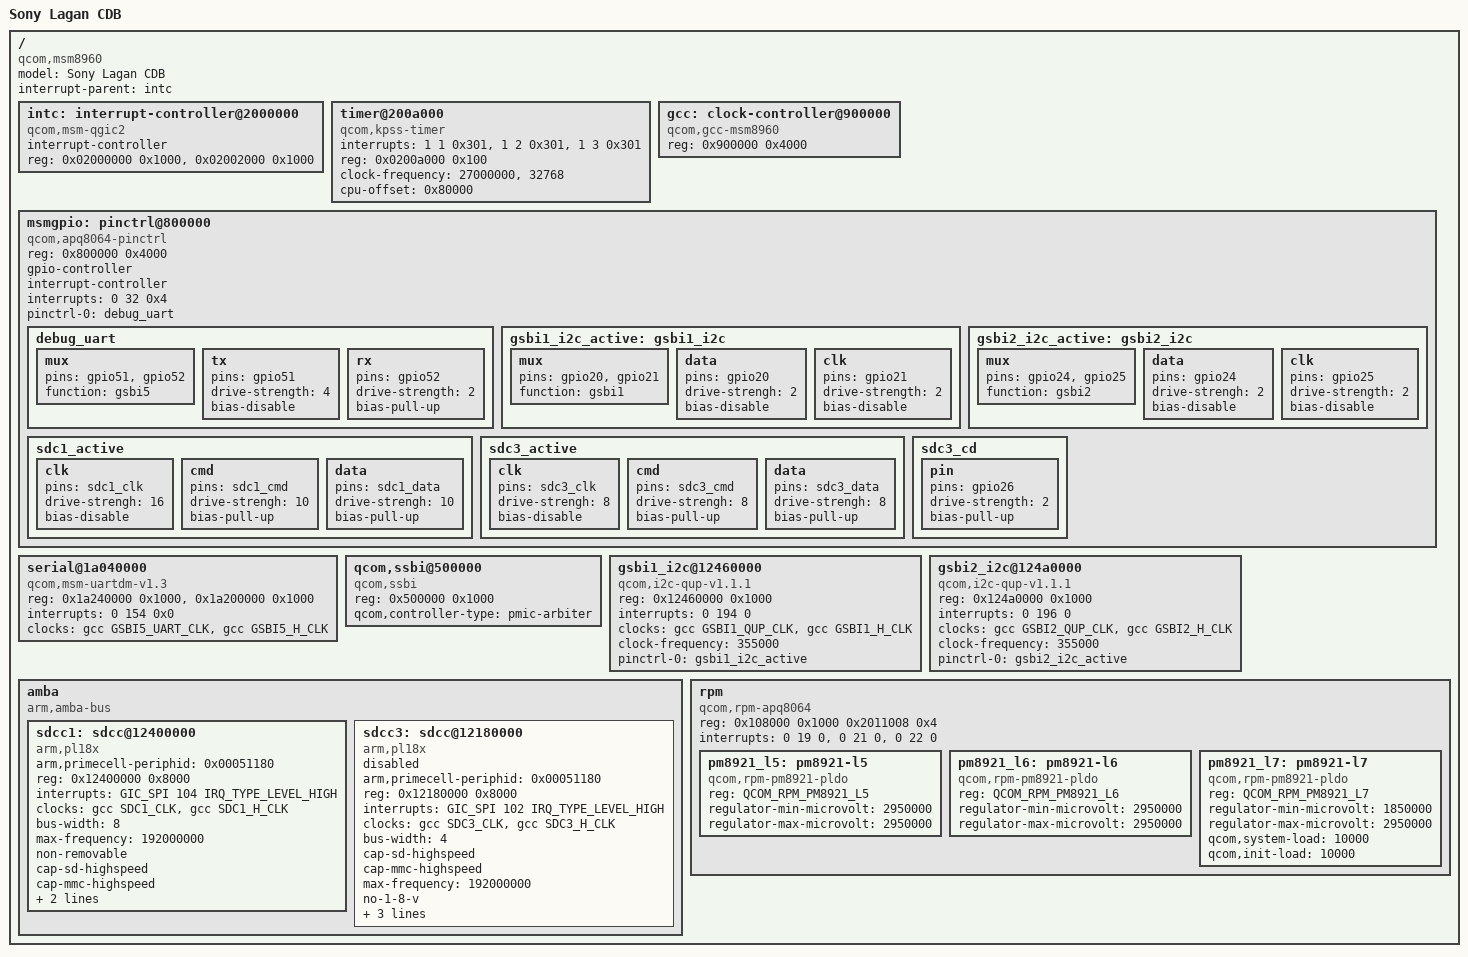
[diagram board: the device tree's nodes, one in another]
/dts-v1/;

#include "skeleton.dtsi"
#include <dt-bindings/interrupt-controller/arm-gic.h>
#include <dt-bindings/clock/qcom,gcc-msm8960.h>

#include <dt-bindings/mfd/qcom_rpm.h>

/ {
	model = "Sony Lagan CDB";
	compatible = "qcom,msm8960";
	interrupt-parent = <&intc>;

	intc: interrupt-controller@2000000 {
		compatible = "qcom,msm-qgic2";
		interrupt-controller;
		#interrupt-cells = <3>;
		reg = < 0x02000000 0x1000 >,
		      < 0x02002000 0x1000 >;
	};

	timer@200a000 {
		compatible = "qcom,kpss-timer", "qcom,msm-timer";
		interrupts = <1 1 0x301>,
			     <1 2 0x301>,
			     <1 3 0x301>;
		reg = <0x0200a000 0x100>;
		clock-frequency = <27000000>,
				  <32768>;
		cpu-offset = <0x80000>;
	};

	gcc: clock-controller@900000 {
		compatible = "qcom,gcc-msm8960";
		reg = <0x900000 0x4000>;
		#clock-cells = <1>;
		#reset-cells = <1>;
	};

	msmgpio: pinctrl@800000 {
		compatible = "qcom,apq8064-pinctrl";
		reg = <0x800000 0x4000>;

		gpio-controller;
		#gpio-cells = <2>;
		interrupt-controller;
		#interrupt-cells = <2>;
		interrupts = <0 32 0x4>;

		pinctrl-names = "default";
		pinctrl-0 = <&debug_uart>;

		debug_uart: debug_uart {
			mux {
				pins = "gpio51", "gpio52";
				function = "gsbi5";
			};

			tx {
				pins = "gpio51";
				drive-strength = <4>;
				bias-disable;
			};

			rx {
				pins = "gpio52";
				drive-strength = <2>;
				bias-pull-up;
			};
		};

		gsbi1_i2c_active: gsbi1_i2c {
			mux {
				pins = "gpio20", "gpio21";
				function = "gsbi1";
			};

			data {
				pins = "gpio20";
				drive-strengh = <2>;
				bias-disable;
			};

			clk {
				pins = "gpio21";
				drive-strength = <2>;
				bias-disable;
			};
		};

		gsbi2_i2c_active: gsbi2_i2c {
			mux {
				pins = "gpio24", "gpio25";
				function = "gsbi2";
			};

			data {
				pins = "gpio24";
				drive-strengh = <2>;
				bias-disable;
			};

			clk {
				pins = "gpio25";
				drive-strength = <2>;
				bias-disable;
			};
		};

		sdc1_active: sdc1_active {
			clk {
				pins = "sdc1_clk";
				drive-strengh = <16>;
				bias-disable;
			};

			cmd {
				pins = "sdc1_cmd";
				drive-strengh = <10>;
				bias-pull-up;
			};

			data {
				pins = "sdc1_data";
				drive-strengh = <10>;
				bias-pull-up;
			};
		};

		sdc3_active: sdc3_active {
			clk {
				pins = "sdc3_clk";
				drive-strengh = <8>;
				bias-disable;
			};

			cmd {
				pins = "sdc3_cmd";
				drive-strengh = <8>;
				bias-pull-up;
			};

			data {
				pins = "sdc3_data";
				drive-strengh = <8>;
				bias-pull-up;
			};
		 };

		sdc3_cd: sdc3_cd {
			pin {
				pins = "gpio26";
				drive-strength = <2>;
				bias-pull-up;
			};
		};
	};

	serial@1a040000 {
		compatible = "qcom,msm-uartdm-v1.3", "qcom,msm-uartdm";
		reg = <0x1a240000 0x1000>,
		      <0x1a200000 0x1000>;
		interrupts = <0 154 0x0>;
		clocks = <&gcc GSBI5_UART_CLK>, <&gcc GSBI5_H_CLK>;
		clock-names = "core", "iface";
	};

	qcom,ssbi@500000 {
		compatible = "qcom,ssbi";
		reg = <0x500000 0x1000>;
		qcom,controller-type = "pmic-arbiter";
	};

	gsbi1_i2c@12460000 {
		compatible = "qcom,i2c-qup-v1.1.1";
		reg = <0x12460000 0x1000>;
		interrupts = <0 194 0>;

		clocks = <&gcc GSBI1_QUP_CLK>, <&gcc GSBI1_H_CLK>;
		clock-names = "core", "iface";

		clock-frequency = <355000>;

		#address-cells = <1>;
		#size-cells = <0>;

		pinctrl-names = "default";
		pinctrl-0 = <&gsbi1_i2c_active>;
	};

	gsbi2_i2c@124a0000 {
		compatible = "qcom,i2c-qup-v1.1.1";
		reg = <0x124a0000 0x1000>;
		interrupts = <0 196 0>;

		clocks = <&gcc GSBI2_QUP_CLK>, <&gcc GSBI2_H_CLK>;
		clock-names = "core", "iface";

		clock-frequency = <355000>;

		#address-cells = <1>;
		#size-cells = <0>;

		pinctrl-names = "default";
		pinctrl-0 = <&gsbi2_i2c_active>;
	};

	amba {
		compatible = "arm,amba-bus";
		#address-cells = <1>;
		#size-cells = <1>;
		ranges;

		sdcc1: sdcc@12400000 {
			compatible      = "arm,pl18x", "arm,primecell";
			arm,primecell-periphid = <0x00051180>;
			reg             = <0x12400000 0x8000>;
			interrupts      = <GIC_SPI 104 IRQ_TYPE_LEVEL_HIGH>;
			interrupt-names = "cmd_irq";
			clocks          = <&gcc SDC1_CLK>, <&gcc SDC1_H_CLK>;
			clock-names     = "mclk", "apb_pclk";
			bus-width       = <8>;
			max-frequency   = <192000000>;
			non-removable;
			cap-sd-highspeed;
			cap-mmc-highspeed;
			vmmc-supply = <&pm8921_l5>;

			pinctrl-names = "default";
			pinctrl-0 = <&sdc1_active>;
		};

		sdcc3: sdcc@12180000 {
			compatible      = "arm,pl18x", "arm,primecell";
			arm,primecell-periphid = <0x00051180>;
			status = "NO!";
			reg             = <0x12180000 0x8000>;
			interrupts      = <GIC_SPI 102 IRQ_TYPE_LEVEL_HIGH>;
			interrupt-names = "cmd_irq";
			clocks          = <&gcc SDC3_CLK>, <&gcc SDC3_H_CLK>;
			clock-names     = "mclk", "apb_pclk";
			bus-width       = <4>;
			cap-sd-highspeed;
			cap-mmc-highspeed;
			max-frequency   = <192000000>;
			no-1-8-v;
			vmmc-supply = <&pm8921_l6>;
			vqmmc-supply = <&pm8921_l7>;

			pinctrl-names = "default";
			pinctrl-0 = <&sdc3_active &sdc3_cd>;
		};
	};

	rpm {
		compatible = "qcom,rpm-apq8064";
		reg = <0x108000 0x1000 0x2011008 0x4>;

		interrupts = <0 19 0>, <0 21 0>, <0 22 0>;
		interrupt-names = "ack", "err", "wakeup";

		#address-cells = <1>;
		#size-cells = <0>;

		pm8921_l5: pm8921-l5 {
			compatible = "qcom,rpm-pm8921-pldo";
			reg = <QCOM_RPM_PM8921_L5>;

			regulator-min-microvolt = <2950000>;
			regulator-max-microvolt = <2950000>;
		};

		pm8921_l6: pm8921-l6 {
			compatible = "qcom,rpm-pm8921-pldo";
			reg = <QCOM_RPM_PM8921_L6>;

			regulator-min-microvolt = <2950000>;
			regulator-max-microvolt = <2950000>;
		};

		pm8921_l7: pm8921-l7 {
			compatible = "qcom,rpm-pm8921-pldo";
			reg = <QCOM_RPM_PM8921_L7>;

			regulator-min-microvolt = <1850000>;
			regulator-max-microvolt = <2950000>;

			qcom,system-load = <10000>;
			qcom,init-load = <10000>;
		};
	};
};
